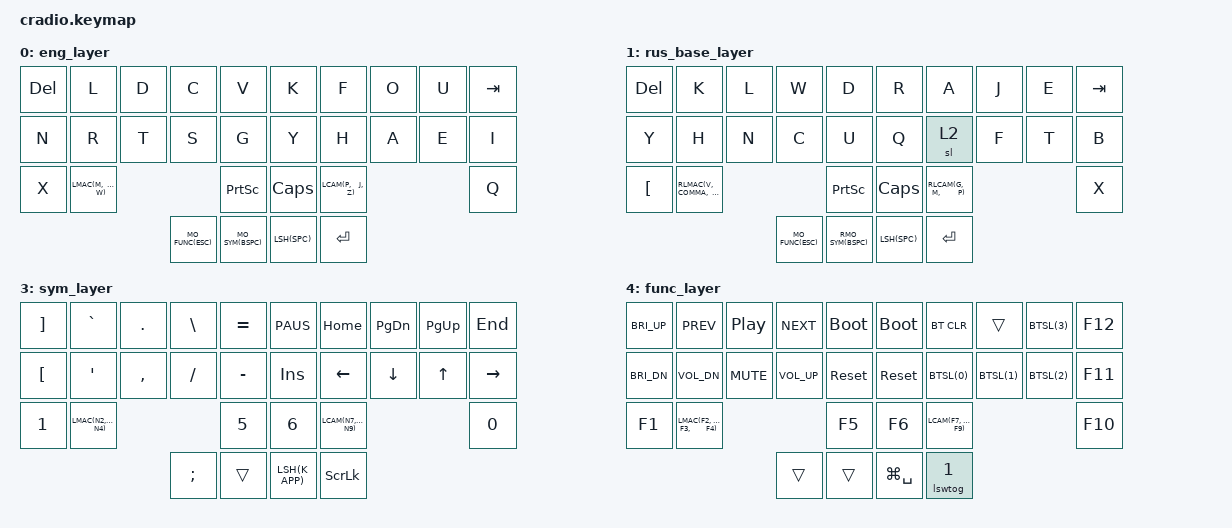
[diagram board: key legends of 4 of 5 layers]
// Copyright (c) 2022 The ZMK Contributors
// SPDX-License-Identifier: MIT

#include <behaviors.dtsi>
#include <dt-bindings/zmk/keys.h>
#include <dt-bindings/zmk/bt.h>

#define LSH(a)         &mdht LSHIFT a
#define LMAC(a, b, c)  &mdht LMETA a &mdht LALT b &mdht LCTRL c
#define LCAM(a, b, c)  &mdht LCTRL a &mdht LALT b &mdht LMETA c
#define MO_SYM(a)      &lrht 3 a
#define MO_FUNC(a)     &lrht 4 a
#define BTSL(a)        &bt BT_SEL a

#define RLMAC(a, b, c)  &rmdht LMETA a &rmdht LALT b &rmdht LCTRL c
#define RLCAM(a, b, c)  &rmdht LCTRL a &rmdht LALT b &rmdht LMETA c
#define RMO_SYM(a)      &rlrht 3 a

/ {

    macros {

        lswtog: lswtog {
            compatible="zmk,behavior-macro-one-param";
            #binding-cells= <1>;
            wait-ms = <5>;
            tap-ms = <10>;
            bindings 
                = <&macro_tap &kp LG(SPC)>
                , <&macro_param_1to1>
                , <&macro_tap &tog MACRO_PLACEHOLDER>
                ;
        };
        
        lswmo: lswmo {
            compatible="zmk,behavior-macro-one-param";
            #binding-cells= <1>;
            wait-ms = <5>;
            tap-ms = <10>;
            bindings 
                = <&macro_tap &kp LG(SPC)>
                , <&macro_tap_time 2>
                , <&macro_wait_time 2>
                , <&macro_param_1to1>
                , <&macro_press &mo MACRO_PLACEHOLDER>
                , <&macro_pause_for_release>
                , <&macro_param_1to1>
                , <&macro_release &mo MACRO_PLACEHOLDER>
                , <&macro_tap_time 10>
                , <&macro_wait_time 5>
                , <&macro_tap &kp LG(SPC)>
                ;
        };

        rmod: rmod {
            compatible="zmk,behavior-macro-one-param";
            #binding-cells= <1>;
            wait-ms = <1>;
            tap-ms = <1>;
            bindings 
                = <&macro_tap &tog 1>
                , <&macro_press &mo 0>
                , <&macro_tap_time 10>
                , <&macro_param_1to1>
                , <&macro_press &kp MACRO_PLACEHOLDER>
                , <&macro_pause_for_release>
                , <&macro_param_1to1>
                , <&macro_release &kp MACRO_PLACEHOLDER>
                , <&macro_tap_time 1>
                , <&macro_release &mo 0>
                , <&macro_tap &tog 1>
                ;
        };
    };

    behaviors {
        mdht: mdht {
            compatible = "zmk,behavior-hold-tap";
            #binding-cells = <2>;
            flavor = "tap-preferred";
            tapping-term-ms = <200>;
            quick-tap-ms = <170>;
            bindings = <&kp>, <&kp>;
        };
        
        rmdht: rmdht {
            compatible = "zmk,behavior-hold-tap";
            #binding-cells = <2>;
            flavor = "tap-preferred";
            tapping-term-ms = <200>;
            quick-tap-ms = <170>;
            bindings = <&rmod>, <&kp>;
        };

        lrht: lrht {
            compatible = "zmk,behavior-hold-tap";
            #binding-cells = <2>;
            flavor = "tap-preferred";
            tapping-term-ms = <200>;
            quick-tap-ms = <170>;
            require-prior-idle-ms = <130>;
            bindings = <&mo>, <&kp>;
        };
        
        rlrht: rlrht {
            compatible = "zmk,behavior-hold-tap";
            #binding-cells = <2>;
            flavor = "tap-preferred";
            tapping-term-ms = <200>;
            quick-tap-ms = <170>;
            require-prior-idle-ms = <130>;
            bindings = <&lswmo>, <&kp>;
        };
    };
    
    keymap {
        compatible = "zmk,keymap";
        eng_layer {
            bindings = <
            &kp DEL    &kp L      &kp D      &kp C         &kp V          &kp K      &kp F      &kp O      &kp U      &kp TAB
            &kp N      &kp R      &kp T      &kp S         &kp G          &kp Y      &kp H      &kp A      &kp E      &kp I
            &kp X      LMAC(M,    B,         W)            &kp PSCRN      &kp CAPS   LCAM(P,    J,         Z)         &kp Q
                                             MO_FUNC(ESC)  MO_SYM(BSPC)   LSH(SPC)   &kp ENTER
            >;
        };

        rus_base_layer {
            bindings = <
            &kp DEL    &kp K      &kp L      &kp W         &kp D          &kp R      &kp A      &kp J      &kp E      &kp TAB
            &kp Y      &kp H      &kp N      &kp C         &kp U          &kp Q      &sl 2      &kp F      &kp T      &kp B
            &kp LBKT   RLMAC(V,    COMMA,     I)           &kp PSCRN      &kp CAPS   RLCAM(G,    M,         P)        &kp X
                                             MO_FUNC(ESC)  RMO_SYM(BSPC)  LSH(SPC)   &kp ENTER
            >;
        };

        rus_combo_layer {
            bindings = <
            &kp DEL    &kp K      &kp L      &kp W         &kp D          &kp R      &kp A      &kp GRAVE  &kp DOT    &kp TAB
            &kp HASH   &kp RA(N8) &kp N      &kp C         &kp U          &kp Q      &kp S      &kp Z      &kp SQT    &kp SEMI
            &kp LBKT   &kp V      &kp COMMA  &kp O         &kp PSCRN      &kp CAPS   &kp G      &kp RBKT   &kp P   &kp X
                                             &kp ESC       &kp BSPC       LSH(SPC)   &kp ENTER
            >;
        };

        sym_layer {
            bindings = <
            &kp RBKT   &kp GRAVE  &kp DOT    &kp BSLH   &kp EQUAL     &kp PAUS   &kp HOME   &kp PG_DN  &kp PG_UP  &kp END
            &kp LBKT   &kp SQT    &kp COMMA  &kp FSLH   &kp MINUS     &kp INS    &kp LEFT   &kp DOWN   &kp UP     &kp RIGHT
            &kp N1     LMAC(N2,   N3,        N4)        &kp N5        &kp N6     LCAM(N7,   N8,        N9)        &kp N0
                                             &kp SEMI   &trans        LSH(K_APP) &kp SLCK
            >;
        };

        func_layer {
            bindings = <
            &kp C_BRI_UP    &kp C_PREV     &kp C_PP   &kp C_NEXT   &bootloader          &bootloader &bt BT_CLR     &trans         BTSL(3)     &kp F12
            &kp C_BRI_DN    &kp C_VOL_DN   &kp C_MUTE &kp C_VOL_UP &sys_reset           &sys_reset  BTSL(0)        BTSL(1)        BTSL(2)     &kp F11
            &kp F1          LMAC(F2,       F3,        F4)          &kp F5               &kp F6      LCAM(F7,       F8,            F9)         &kp F10
                                                      &trans       &trans               &kp LG(SPC) &lswtog 1
            >;
        };
    };
};
